# TC35678 register map
Vendor: Toshiba Electronic Devices and Storage Corporation; File version: 0.1
CPU: CM0 r0p0, little endian, no MPU, no FPU, 4 interrupt priority bits
Registers are 32-bit, read-write, no defined reset value unless marked. A register's access mark holds for its fields unless they carry their own. Offsets are from the block's base; [hi:lo] are bit positions; {n}, {i} and the like mark numbered series.

## Clock — Clock Supply for SPI and PWM
Base 0x4004C000
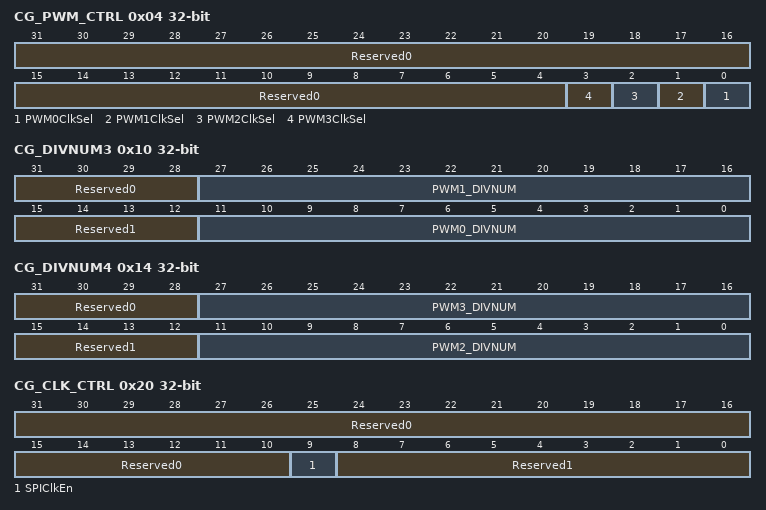
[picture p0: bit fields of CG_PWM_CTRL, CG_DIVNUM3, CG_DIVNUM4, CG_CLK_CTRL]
0x04 CG_PWM_CTRL — PWM clock mode set
  [31:4] Reserved0 — Do not change the values.
  [n] PWM{n}ClkSel (n=0..3) — Select PWM{n} clock 1: MAX 13 MHz (This division ratio can be changed in CG_DIVNUM4) 0: 32 kHz Please set disable to PWM{n}SlpClkEn and PWM{n}ClkEn before changing this register.
0x10 CG_DIVNUM3 — Division ration for PWM1 and PWM0 config
  [31:28] Reserved0 — Do not change the values.
  [27:16] PWM1_DIVNUM — Division ratio of 26MHz clock to generate PWM1 clock. PWM1 clock ON/OFF can be set on CG_CLK_CTRL2 register. This value can be changed regardless of the clock ON/OFF. However, the output clock may be unstable right after the change of this register. division ratio = (this value + 1) * 2 default value is 0x000 (Divided by 2)
  [15:12] Reserved1 — Do not change the values.
  [11:0] PWM0_DIVNUM — Division ratio of 26MHz clock to generate PWM0 clock. PWM0 clock ON/OFF can be set on CG_CLK_CTRL2 register. This value can be changed regardless of the clock ON/OFF. However, the output clock may be unstable right after the change of this register. division ratio = (this value + 1) * 2 default value is 0x000 (Divided by 2)
0x14 CG_DIVNUM4 — Division ration for PWM3 and PWM2 config
  [31:28] Reserved0 — Do not change the values.
  [27:16] PWM3_DIVNUM — Division ratio of 26MHz clock to generate PWM3 clock. PWM3 clock ON/OFF can be set on CG_CLK_CTRL2 register. This value can be changed regardless of the clock ON/OFF. However, the output clock may be unstable right after the change of this register. division ratio = (this value + 1) * 2 default value is 0x000 (Divided by 2)
  [15:12] Reserved1 — Do not change the values.
  [11:0] PWM2_DIVNUM — Division ratio of 26MHz clock to generate PWM2 clock. PWM2 clock ON/OFF can be set on CG_CLK_CTRL2 register. This value can be changed regardless of the clock ON/OFF. However, the output clock may be unstable right after the change of this register. division ratio = (this value + 1) * 2 default value is 0x000 (Divided by 2)
0x20 CG_CLK_CTRL — SPI Clock control
  [31:10] Reserved0 — Do not change the values.
  [9] SPIClkEn — Enable SPI clock (R/W) 1: Enable clock 0: Disable clock (default)
  [8:0] Reserved1 — Do not change the values.
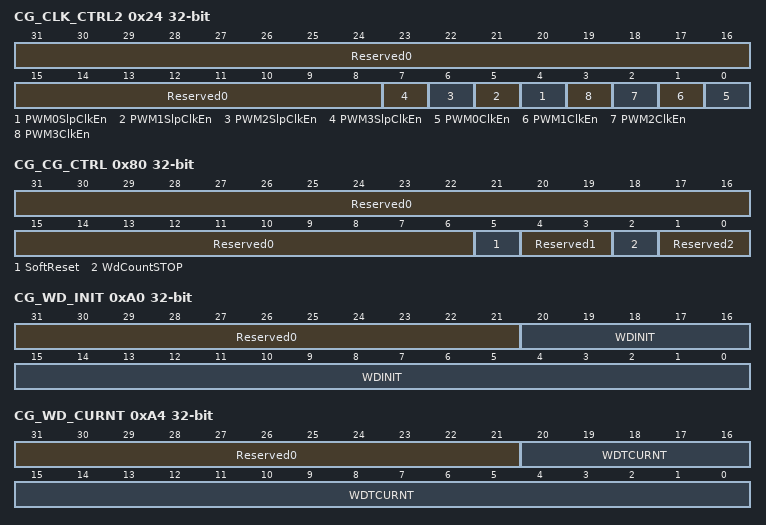
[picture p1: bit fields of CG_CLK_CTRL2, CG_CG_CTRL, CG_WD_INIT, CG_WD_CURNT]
0x24 CG_CLK_CTRL2 — PWM Clock Control
  [31:8] Reserved0 — Do not change the values.
  [n+4] PWM{n}SlpClkEn (n=0..3) — Enable PWM ch {n} slow clock (R/W) 1: Enable clock 0: Disable clock (default)
  [n] PWM{n}ClkEn (n=0..3) — Enable PWM ch {n} fast clock (R/W) 1: Enable clock 0: Disable clock (default)
0x80 CG_CG_CTRL — ckgn config register
  [31:6] Reserved0 — Do not change the values.
  [5] SoftReset — Soft-Reset control 1: Soft-Reset 0: No change
  [4:3] Reserved1 — Do not change the values.
  [2] WdCountSTOP — Start or stop WDT counter 1: Stop counter 0: Start counter When set 1, WDT counter suspends. When set 0, WDT counter resumes. During the system state is low power mode, WDT does not count.
  [1:0] Reserved2 — Do not change the values.
0xA0 CG_WD_INIT — Watchdog initial register
  [31:21] Reserved0 — Do not change the values.
  [20:0] WDINIT — Set initial value of WDT counter This value can be set from 0x1(30.5 micro seconds) to 0x1FFFFF.(64 seconds) Setting time is calculated as below: setting time = (this value) * 30.5 micro seconds When you update this value, please wait for more than 2 clocks of SleepClk(32kHz clock) since the previous change. When the system wakes up from low power mode, WDT counter is set this value.
0xA4 CG_WD_CURNT — Watchdog current register
  [31:21] Reserved0 — Do not change the values.
  [20:0] WDTCURNT — Watchdog current value When the system wakes up from low power mode, this value becomes WDINIT value.
